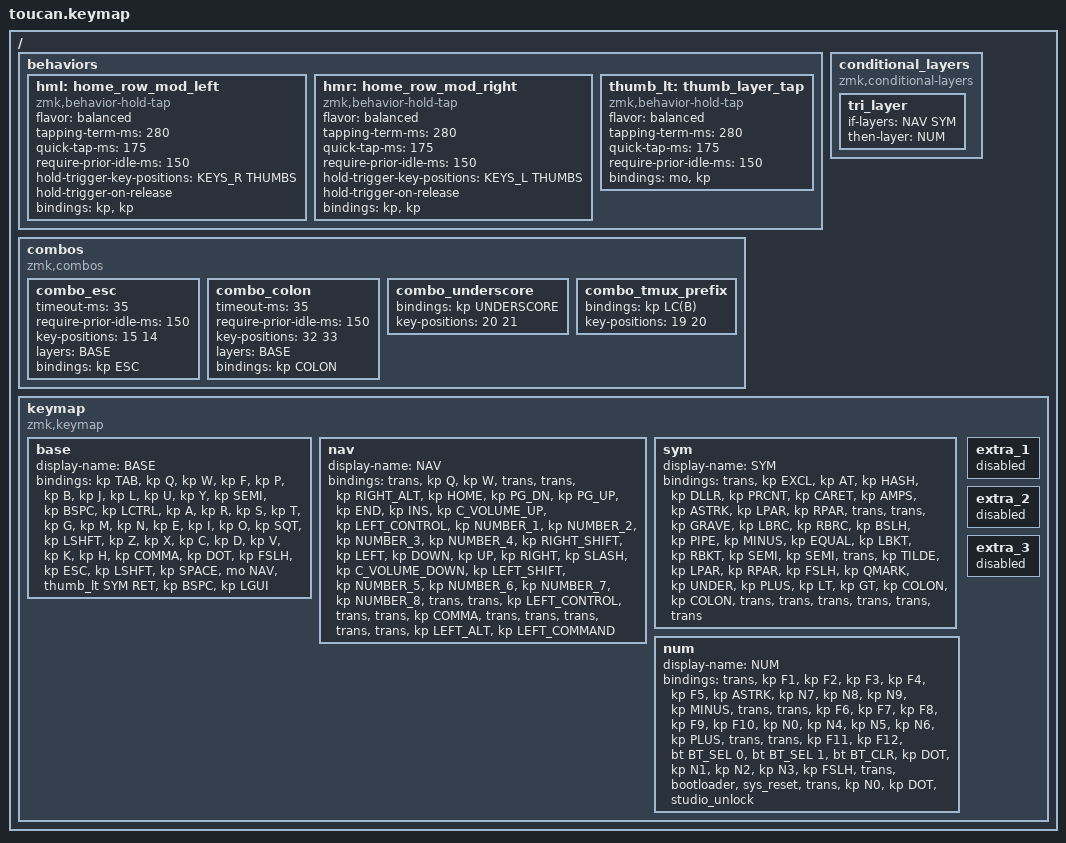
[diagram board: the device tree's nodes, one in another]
/*
 * beekeeb Toucan — Colemak-DH keymap with homerow mods + 4 layers
 * ────────────────────────────────────────────────────────────────────────
 * This is ZMK FIRMWARE config, not nvim config. To use it:
 *   1. Fork github.com/beekeeb/zmk-keyboard-toucan
 *   2. Copy this file to  config/toucan.keymap  in your fork (overwrite)
 *   3. git push → GitHub Actions builds left/right .uf2 → flash both halves
 * Edit live with ZMK Studio (zmk.studio) once flashed.
 *
 * Physical key positions (used by hold-trigger-key-positions below):
 *
 *   0   1   2   3   4   5         6   7   8   9  10  11
 *  12  13  14  15  16  17        18  19  20  21  22  23
 *  24  25  26  27  28  29        30  31  32  33  34  35
 *              36  37  38        39  40  41
 *
 * Base layer (Colemak Mod-DH). Homerow mods are DISABLED for now — the hml/hmr
 * behaviors below are kept so they can be re-enabled by swapping the home-row
 * bindings back (e.g.  &kp A  ->  &hml LGUI A).
 * Modifiers without HRMs: LCTRL/LSHFT on the left outer column, LGUI on the
 * left thumb, RSHFT on the right outer thumb (for capitals of left-hand
 * letters), and one-shot mod chords via the NAV layer's left home row.
 */

#include <behaviors.dtsi>
#include <dt-bindings/zmk/bt.h>
#include <dt-bindings/zmk/keys.h>

#define BASE 0
#define NAV  1
#define SYM  2
#define NUM  3

// Position groups for positional (per-hand) homerow mods.
// A homerow mod only acts as a *hold* if a key on the OPPOSITE hand (or a
// thumb) is pressed — this kills same-hand misfires while typing fast.

#define KEYS_L 0 1 2 3 4 5 12 13 14 15 16 17 24 25 26 27 28 29
#define KEYS_R 6 7 8 9 10 11 18 19 20 21 22 23 30 31 32 33 34 35
#define THUMBS 36 37 38 39 40 41

/ {
    behaviors {
        // urob-style "timeless" homerow mods — balanced flavor, positional,
        // require-prior-idle to suppress mods during fast rolls.

        hml: home_row_mod_left {
            compatible = "zmk,behavior-hold-tap";
            #binding-cells = <2>;
            flavor = "balanced";
            tapping-term-ms = <280>;
            quick-tap-ms = <175>;
            require-prior-idle-ms = <150>;
            hold-trigger-key-positions = <KEYS_R THUMBS>;
            hold-trigger-on-release;
            bindings = <&kp>, <&kp>;
        };

        hmr: home_row_mod_right {
            compatible = "zmk,behavior-hold-tap";
            #binding-cells = <2>;
            flavor = "balanced";
            tapping-term-ms = <280>;
            quick-tap-ms = <175>;
            require-prior-idle-ms = <150>;
            hold-trigger-key-positions = <KEYS_L THUMBS>;
            hold-trigger-on-release;
            bindings = <&kp>, <&kp>;
        };

        // Thumb layer-tap — same urob timing as the HRMs, minus the positional
        // gate (thumbs aren't rolled into alpha sequences, so it's not needed).
        // bindings: hold -> &mo (momentary layer), tap -> &kp (keycode).

        thumb_lt: thumb_layer_tap {
            compatible = "zmk,behavior-hold-tap";
            #binding-cells = <2>;
            flavor = "balanced";
            tapping-term-ms = <280>;
            quick-tap-ms = <175>;
            require-prior-idle-ms = <150>;
            bindings = <&mo>, <&kp>;
        };
    };

    combos {
        compatible = "zmk,combos";

        // R+S (ring+middle, left home row) → ESC. require-prior-idle keeps it
        // from firing mid-roll while typing; the corner ESC at pos 35 stays as
        // a fallback.

        combo_esc {
            timeout-ms = <35>;
            require-prior-idle-ms = <150>;
            key-positions = <15 14>;
            layers = <BASE>;
            bindings = <&kp ESC>;
        };

        // ,+. (comma+dot, right middle+ring) → ':' for fast vim :w / :q.
        // Chosen over .+/ because './' is a real typing sequence in paths.

        combo_colon {
            timeout-ms = <35>;
            require-prior-idle-ms = <150>;
            key-positions = <32 33>;
            layers = <BASE>;
            bindings = <&kp COLON>;
        };

        combo_underscore {
            bindings = <&kp UNDERSCORE>;
            key-positions = <20 21>;
        };

        combo_tmux_prefix {
            bindings = <&kp LC(B)>;
            key-positions = <19 20>;
        };
    };

    conditional_layers {
        compatible = "zmk,conditional-layers";

        // Hold both thumb layer-keys (NAV + SYM) → NUM.

        tri_layer {
            if-layers = <NAV SYM>;
            then-layer = <NUM>;
        };
    };

    keymap {
        compatible = "zmk,keymap";

        base {
            display-name = "BASE";
            bindings = <
&kp TAB  &kp Q  &kp W  &kp F  &kp P  &kp B  &kp J  &kp L  &kp U  &kp Y  &kp SEMI  &kp BSPC  &kp LCTRL  &kp A  &kp R  &kp S  &kp T  &kp G  &kp M  &kp N  &kp E  &kp I  &kp O  &kp SQT  &kp LSHFT  &kp Z  &kp X  &kp C  &kp D  &kp V  &kp K  &kp H  &kp COMMA  &kp DOT  &kp FSLH  &kp ESC  &kp LSHFT  &kp SPACE  &mo NAV  &thumb_lt SYM RET  &kp BSPC  &kp LGUI
            >;
        };

        nav {
            display-name = "NAV";
            bindings = <
&trans  &kp Q  &kp W  &trans  &trans  &kp RIGHT_ALT  &kp HOME  &kp PG_DN  &kp PG_UP  &kp END  &kp INS  &kp C_VOLUME_UP  &kp LEFT_CONTROL  &kp NUMBER_1  &kp NUMBER_2  &kp NUMBER_3  &kp NUMBER_4  &kp RIGHT_SHIFT  &kp LEFT  &kp DOWN  &kp UP  &kp RIGHT  &kp SLASH  &kp C_VOLUME_DOWN  &kp LEFT_SHIFT  &kp NUMBER_5  &kp NUMBER_6  &kp NUMBER_7  &kp NUMBER_8  &trans  &trans  &kp LEFT_CONTROL  &trans  &trans  &kp COMMA  &trans  &trans  &trans  &trans  &trans  &kp LEFT_ALT  &kp LEFT_COMMAND
            >;
        };

        sym {
            display-name = "SYM";
            bindings = <
&trans  &kp EXCL  &kp AT  &kp HASH  &kp DLLR  &kp PRCNT  &kp CARET  &kp AMPS  &kp ASTRK  &kp LPAR  &kp RPAR  &trans  &trans  &kp GRAVE  &kp LBRC  &kp RBRC  &kp BSLH  &kp PIPE  &kp MINUS  &kp EQUAL  &kp LBKT  &kp RBKT  &kp SEMI  &kp SEMI  &trans  &kp TILDE  &kp LPAR  &kp RPAR  &kp FSLH  &kp QMARK  &kp UNDER  &kp PLUS  &kp LT  &kp GT  &kp COLON  &kp COLON  &trans  &trans  &trans  &trans  &trans  &trans
            >;
        };

        num {
            display-name = "NUM";
            bindings = <
&trans  &kp F1  &kp F2  &kp F3  &kp F4  &kp F5  &kp ASTRK  &kp N7  &kp N8  &kp N9  &kp MINUS  &trans  &trans  &kp F6  &kp F7  &kp F8  &kp F9  &kp F10  &kp N0  &kp N4  &kp N5  &kp N6  &kp PLUS  &trans  &trans  &kp F11  &kp F12  &bt BT_SEL 0  &bt BT_SEL 1  &bt BT_CLR  &kp DOT  &kp N1  &kp N2  &kp N3  &kp FSLH  &trans  &bootloader  &sys_reset  &trans  &kp N0  &kp DOT  &studio_unlock
            >;
        };

        // Reserved so ZMK Studio can add layers at runtime. Leave as-is.

        extra_1 { status = "reserved"; };

        extra_2 { status = "reserved"; };

        extra_3 { status = "reserved"; };
    };
};
